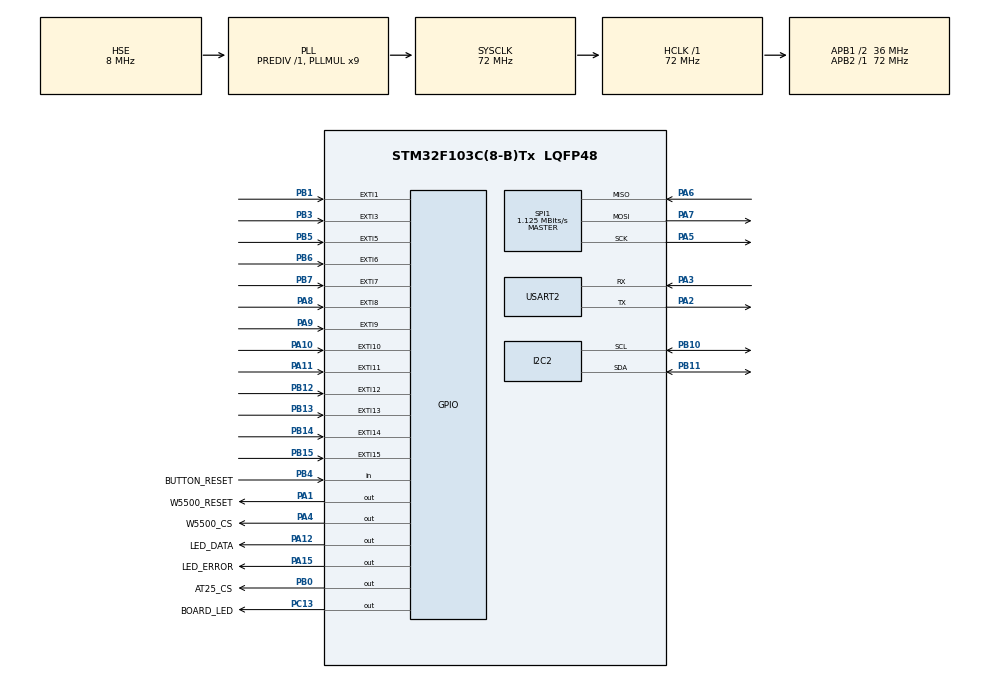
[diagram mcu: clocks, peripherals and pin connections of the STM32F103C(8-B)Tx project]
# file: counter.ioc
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Mcu.Family=STM32F1
Mcu.Name=STM32F103C(8-B)Tx
Mcu.Package=LQFP48
NVIC.EXTI15_10_IRQn=true\:0\:0\:false\:false\:true\:true\:true
NVIC.EXTI1_IRQn=true\:0\:0\:false\:false\:true\:true\:true
NVIC.EXTI3_IRQn=true\:0\:0\:false\:false\:true\:true\:true
NVIC.EXTI9_5_IRQn=true\:0\:0\:false\:false\:true\:true\:true
NVIC.PriorityGroup=NVIC_PRIORITYGROUP_4
PA1.GPIO_Label=W5500_RESET
PA1.PinState=GPIO_PIN_SET
PA1.Signal=GPIO_Output
PA10.GPIO_PuPd=GPIO_PULLDOWN
PA10.Signal=GPXTI10
PA11.GPIO_PuPd=GPIO_PULLDOWN
PA11.Signal=GPXTI11
PA12.GPIO_Label=LED_DATA
PA12.Signal=GPIO_Output
PA13.Mode=Serial_Wire
PA13.Signal=SYS_JTMS-SWDIO
PA14.Mode=Serial_Wire
PA14.Signal=SYS_JTCK-SWCLK
PA15.GPIO_Label=LED_ERROR
PA15.Signal=GPIO_Output
PA2.Mode=Asynchronous
PA2.Signal=USART2_TX
PA3.Mode=Asynchronous
PA3.Signal=USART2_RX
PA4.GPIO_Label=W5500_CS
PA4.PinState=GPIO_PIN_SET
PA4.Signal=GPIO_Output
PA5.Mode=Full_Duplex_Master
PA5.Signal=SPI1_SCK
PA6.Mode=Full_Duplex_Master
PA6.Signal=SPI1_MISO
PA7.Mode=Full_Duplex_Master
PA7.Signal=SPI1_MOSI
PA8.GPIO_PuPd=GPIO_PULLDOWN
PA8.Signal=GPXTI8
PA9.GPIO_PuPd=GPIO_PULLDOWN
PA9.Signal=GPXTI9
PB0.GPIO_Label=AT25_CS
PB0.PinState=GPIO_PIN_SET
PB0.Signal=GPIO_Output
PB1.GPIO_ModeDefaultEXTI=GPIO_MODE_IT_FALLING
PB1.GPIO_PuPd=GPIO_PULLUP
PB1.Signal=GPXTI1
PB10.Mode=I2C
PB10.Signal=I2C2_SCL
PB11.Mode=I2C
PB11.Signal=I2C2_SDA
PB12.GPIO_PuPd=GPIO_PULLDOWN
PB12.Signal=GPXTI12
PB13.GPIO_PuPd=GPIO_PULLDOWN
PB13.Signal=GPXTI13
PB14.GPIO_PuPd=GPIO_PULLDOWN
PB14.Signal=GPXTI14
PB15.GPIO_PuPd=GPIO_PULLDOWN
PB15.Signal=GPXTI15
PB3.GPIO_PuPd=GPIO_PULLDOWN
PB3.Signal=GPXTI3
PB4.GPIO_Label=BUTTON_RESET
PB4.GPIO_PuPd=GPIO_PULLUP
PB4.Signal=GPIO_Input
PB5.GPIO_PuPd=GPIO_PULLDOWN
PB5.Signal=GPXTI5
PB6.GPIO_PuPd=GPIO_PULLDOWN
PB6.Signal=GPXTI6
PB7.GPIO_PuPd=GPIO_PULLDOWN
PB7.Signal=GPXTI7
PC13-TAMPER-RTC.GPIO_Label=BOARD_LED
PC13-TAMPER-RTC.Signal=GPIO_Output
PC14-OSC32_IN.Mode=LSE-External-Oscillator
PC14-OSC32_IN.Signal=RCC_OSC32_IN
PC15-OSC32_OUT.Mode=LSE-External-Oscillator
PC15-OSC32_OUT.Signal=RCC_OSC32_OUT
PD0-OSC_IN.Mode=HSE-External-Oscillator
PD0-OSC_IN.Signal=RCC_OSC_IN
PD1-OSC_OUT.Mode=HSE-External-Oscillator
PD1-OSC_OUT.Signal=RCC_OSC_OUT
ProjectManager.HeapSize=0x200
ProjectManager.StackSize=0x400
ProjectManager.TargetToolchain=STM32CubeIDE
RCC.AHBFreq_Value=72000000
RCC.APB1CLKDivider=RCC_HCLK_DIV2
RCC.APB1Freq_Value=36000000
RCC.APB1TimFreq_Value=72000000
RCC.APB2Freq_Value=72000000
RCC.APB2TimFreq_Value=72000000
RCC.HCLKFreq_Value=72000000
RCC.PLLMUL=RCC_PLL_MUL9
RCC.PLLSourceVirtual=RCC_PLLSOURCE_HSE
RCC.SYSCLKFreq_VALUE=72000000
RCC.SYSCLKSource=RCC_SYSCLKSOURCE_PLLCLK
RCC.USBFreq_Value=72000000
SPI1.BaudRatePrescaler=SPI_BAUDRATEPRESCALER_64
SPI1.CalculateBaudRate=1.125 MBits/s
SPI1.Direction=SPI_DIRECTION_2LINES
SPI1.Mode=SPI_MODE_MASTER
SPI1.VirtualType=VM_MASTER
USART2.VirtualMode=VM_ASYNC
board=custom

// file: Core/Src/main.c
/* USER CODE BEGIN Header */
/**
  ******************************************************************************
  * @file           : main.c
  * @brief          : Main program body
  ******************************************************************************
  * @attention
  *
  * <h2><center>&copy; Copyright (c) 2021 STMicroelectronics.
  * All rights reserved.</center></h2>
  *
  * This software component is licensed by ST under BSD 3-Clause license,
  * the "License"; You may not use this file except in compliance with the
  * License. You may obtain a copy of the License at:
  *                        opensource.org/licenses/BSD-3-Clause
  *
  ******************************************************************************
  */
/* USER CODE END Header */
#include "main.h"

I2C_HandleTypeDef hi2c2;

SPI_HandleTypeDef hspi1;

UART_HandleTypeDef huart2;

void SystemClock_Config(void);
static void MX_GPIO_Init(void);
static void MX_I2C2_Init(void);
static void MX_SPI1_Init(void);
static void MX_USART2_UART_Init(void);

/* USER CODE BEGIN 0 */
void debug_printf(const char * fmt, ...) {
  #ifdef DEBUG_UART
  char buf[DEBUG_FMT_MAX_SIZE];
  va_list argptr;
  va_start(argptr, fmt);
  int len = vsnprintf(buf, DEBUG_FMT_MAX_SIZE, fmt, argptr);
  va_end(argptr);
  HAL_UART_Transmit(&huart2, buf, len, 300);
  #endif
}

/* USER CODE END 0 */

int main(void)
{

  /* MCU Configuration--------------------------------------------------------*/

  /* Reset of all peripherals, Initializes the Flash interface and the Systick. */
  HAL_Init();

  /* Configure the system clock */
  SystemClock_Config();

  /* Initialize all configured peripherals */
  MX_GPIO_Init();
  MX_I2C2_Init();
  MX_SPI1_Init();
  MX_USART2_UART_Init();
  /* USER CODE BEGIN 2 */
  counter_init();

  /* USER CODE END 2 */

  /* Infinite loop */
  /* USER CODE BEGIN WHILE */
  while (1)
  {
    event_loop();
    /* USER CODE END WHILE */

  }
}

void SystemClock_Config(void)
{
  RCC_OscInitTypeDef RCC_OscInitStruct = {0};
  RCC_ClkInitTypeDef RCC_ClkInitStruct = {0};

  /** Initializes the RCC Oscillators according to the specified parameters
  * in the RCC_OscInitTypeDef structure.
  */
  RCC_OscInitStruct.OscillatorType = RCC_OSCILLATORTYPE_HSE;
  RCC_OscInitStruct.HSEState = RCC_HSE_ON;
  RCC_OscInitStruct.HSEPredivValue = RCC_HSE_PREDIV_DIV1;
  RCC_OscInitStruct.HSIState = RCC_HSI_ON;
  RCC_OscInitStruct.PLL.PLLState = RCC_PLL_ON;
  RCC_OscInitStruct.PLL.PLLSource = RCC_PLLSOURCE_HSE;
  RCC_OscInitStruct.PLL.PLLMUL = RCC_PLL_MUL9;
  if (HAL_RCC_OscConfig(&RCC_OscInitStruct) != HAL_OK)
  {
    Error_Handler();
  }
  /** Initializes the CPU, AHB and APB buses clocks
  */
  RCC_ClkInitStruct.ClockType = RCC_CLOCKTYPE_HCLK|RCC_CLOCKTYPE_SYSCLK
                              |RCC_CLOCKTYPE_PCLK1|RCC_CLOCKTYPE_PCLK2;
  RCC_ClkInitStruct.SYSCLKSource = RCC_SYSCLKSOURCE_PLLCLK;
  RCC_ClkInitStruct.AHBCLKDivider = RCC_SYSCLK_DIV1;
  RCC_ClkInitStruct.APB1CLKDivider = RCC_HCLK_DIV2;
  RCC_ClkInitStruct.APB2CLKDivider = RCC_HCLK_DIV1;

  if (HAL_RCC_ClockConfig(&RCC_ClkInitStruct, FLASH_LATENCY_2) != HAL_OK)
  {
    Error_Handler();
  }
}

static void MX_I2C2_Init(void)
{

  hi2c2.Instance = I2C2;
  hi2c2.Init.ClockSpeed = 100000;
  hi2c2.Init.DutyCycle = I2C_DUTYCYCLE_2;
  hi2c2.Init.OwnAddress1 = 0;
  hi2c2.Init.AddressingMode = I2C_ADDRESSINGMODE_7BIT;
  hi2c2.Init.DualAddressMode = I2C_DUALADDRESS_DISABLE;
  hi2c2.Init.OwnAddress2 = 0;
  hi2c2.Init.GeneralCallMode = I2C_GENERALCALL_DISABLE;
  hi2c2.Init.NoStretchMode = I2C_NOSTRETCH_DISABLE;
  if (HAL_I2C_Init(&hi2c2) != HAL_OK)
  {
    Error_Handler();
  }

}

static void MX_SPI1_Init(void)
{

  /* SPI1 parameter configuration*/
  hspi1.Instance = SPI1;
  hspi1.Init.Mode = SPI_MODE_MASTER;
  hspi1.Init.Direction = SPI_DIRECTION_2LINES;
  hspi1.Init.DataSize = SPI_DATASIZE_8BIT;
  hspi1.Init.CLKPolarity = SPI_POLARITY_LOW;
  hspi1.Init.CLKPhase = SPI_PHASE_1EDGE;
  hspi1.Init.NSS = SPI_NSS_SOFT;
  hspi1.Init.BaudRatePrescaler = SPI_BAUDRATEPRESCALER_64;
  hspi1.Init.FirstBit = SPI_FIRSTBIT_MSB;
  hspi1.Init.TIMode = SPI_TIMODE_DISABLE;
  hspi1.Init.CRCCalculation = SPI_CRCCALCULATION_DISABLE;
  hspi1.Init.CRCPolynomial = 10;
  if (HAL_SPI_Init(&hspi1) != HAL_OK)
  {
    Error_Handler();
  }

}

static void MX_USART2_UART_Init(void)
{

  huart2.Instance = USART2;
  huart2.Init.BaudRate = 115200;
  huart2.Init.WordLength = UART_WORDLENGTH_8B;
  huart2.Init.StopBits = UART_STOPBITS_1;
  huart2.Init.Parity = UART_PARITY_NONE;
  huart2.Init.Mode = UART_MODE_TX_RX;
  huart2.Init.HwFlowCtl = UART_HWCONTROL_NONE;
  huart2.Init.OverSampling = UART_OVERSAMPLING_16;
  if (HAL_UART_Init(&huart2) != HAL_OK)
  {
    Error_Handler();
  }

}

static void MX_GPIO_Init(void)
{
  GPIO_InitTypeDef GPIO_InitStruct = {0};

  /* GPIO Ports Clock Enable */
  __HAL_RCC_GPIOC_CLK_ENABLE();
  __HAL_RCC_GPIOD_CLK_ENABLE();
  __HAL_RCC_GPIOA_CLK_ENABLE();
  __HAL_RCC_GPIOB_CLK_ENABLE();

  /*Configure GPIO pin Output Level */
  HAL_GPIO_WritePin(BOARD_LED_GPIO_Port, BOARD_LED_Pin, GPIO_PIN_RESET);

  /*Configure GPIO pin Output Level */
  HAL_GPIO_WritePin(GPIOA, W5500_RESET_Pin|W5500_CS_Pin, GPIO_PIN_SET);

  /*Configure GPIO pin Output Level */
  HAL_GPIO_WritePin(AT25_CS_GPIO_Port, AT25_CS_Pin, GPIO_PIN_SET);

  /*Configure GPIO pin Output Level */
  HAL_GPIO_WritePin(GPIOA, LED_DATA_Pin|LED_ERROR_Pin, GPIO_PIN_RESET);

  /*Configure GPIO pin : BOARD_LED_Pin */
  GPIO_InitStruct.Pin = BOARD_LED_Pin;
  GPIO_InitStruct.Mode = GPIO_MODE_OUTPUT_PP;
  GPIO_InitStruct.Pull = GPIO_NOPULL;
  GPIO_InitStruct.Speed = GPIO_SPEED_FREQ_LOW;
  HAL_GPIO_Init(BOARD_LED_GPIO_Port, &GPIO_InitStruct);

  /*Configure GPIO pins : W5500_RESET_Pin W5500_CS_Pin LED_DATA_Pin LED_ERROR_Pin */
  GPIO_InitStruct.Pin = W5500_RESET_Pin|W5500_CS_Pin|LED_DATA_Pin|LED_ERROR_Pin;
  GPIO_InitStruct.Mode = GPIO_MODE_OUTPUT_PP;
  GPIO_InitStruct.Pull = GPIO_NOPULL;
  GPIO_InitStruct.Speed = GPIO_SPEED_FREQ_LOW;
  HAL_GPIO_Init(GPIOA, &GPIO_InitStruct);

  /*Configure GPIO pin : AT25_CS_Pin */
  GPIO_InitStruct.Pin = AT25_CS_Pin;
  GPIO_InitStruct.Mode = GPIO_MODE_OUTPUT_PP;
  GPIO_InitStruct.Pull = GPIO_NOPULL;
  GPIO_InitStruct.Speed = GPIO_SPEED_FREQ_LOW;
  HAL_GPIO_Init(AT25_CS_GPIO_Port, &GPIO_InitStruct);

  /*Configure GPIO pin : PB1 */
  GPIO_InitStruct.Pin = GPIO_PIN_1;
  GPIO_InitStruct.Mode = GPIO_MODE_IT_FALLING;
  GPIO_InitStruct.Pull = GPIO_PULLUP;
  HAL_GPIO_Init(GPIOB, &GPIO_InitStruct);

  /*Configure GPIO pins : PB12 PB13 PB14 PB15
                           PB3 PB5 PB6 PB7 */
  GPIO_InitStruct.Pin = GPIO_PIN_12|GPIO_PIN_13|GPIO_PIN_14|GPIO_PIN_15
                          |GPIO_PIN_3|GPIO_PIN_5|GPIO_PIN_6|GPIO_PIN_7;
  GPIO_InitStruct.Mode = GPIO_MODE_IT_RISING;
  GPIO_InitStruct.Pull = GPIO_PULLDOWN;
  HAL_GPIO_Init(GPIOB, &GPIO_InitStruct);

  /*Configure GPIO pins : PA8 PA9 PA10 PA11 */
  GPIO_InitStruct.Pin = GPIO_PIN_8|GPIO_PIN_9|GPIO_PIN_10|GPIO_PIN_11;
  GPIO_InitStruct.Mode = GPIO_MODE_IT_RISING;
  GPIO_InitStruct.Pull = GPIO_PULLDOWN;
  HAL_GPIO_Init(GPIOA, &GPIO_InitStruct);

  /*Configure GPIO pin : BUTTON_RESET_Pin */
  GPIO_InitStruct.Pin = BUTTON_RESET_Pin;
  GPIO_InitStruct.Mode = GPIO_MODE_INPUT;
  GPIO_InitStruct.Pull = GPIO_PULLUP;
  HAL_GPIO_Init(BUTTON_RESET_GPIO_Port, &GPIO_InitStruct);

  /* EXTI interrupt init*/
  HAL_NVIC_SetPriority(EXTI1_IRQn, 0, 0);
  HAL_NVIC_EnableIRQ(EXTI1_IRQn);

  HAL_NVIC_SetPriority(EXTI3_IRQn, 0, 0);
  HAL_NVIC_EnableIRQ(EXTI3_IRQn);

  HAL_NVIC_SetPriority(EXTI9_5_IRQn, 0, 0);
  HAL_NVIC_EnableIRQ(EXTI9_5_IRQn);

  HAL_NVIC_SetPriority(EXTI15_10_IRQn, 0, 0);
  HAL_NVIC_EnableIRQ(EXTI15_10_IRQn);

}

void Error_Handler(void)
{
  __disable_irq();
  while (1)
  {
  }
}

/************************ (C) COPYRIGHT STMicroelectronics *****END OF FILE****/
